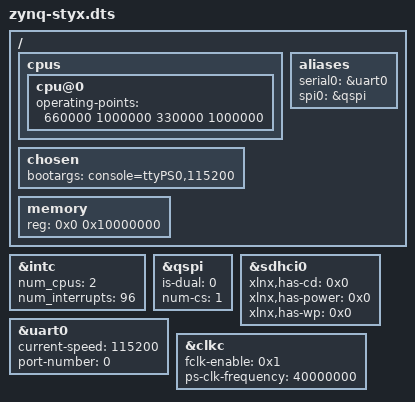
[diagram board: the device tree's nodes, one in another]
/*
 * CAUTION: This file is automatically generated by Xilinx.
 * Version:  
 * Today is: Thu Aug 11 10:48:36 2016
*/


/dts-v1/;
/include/ "zynq-7000.dtsi"
/ {
	cpus {
		cpu@0 {
			operating-points = <660000 1000000 330000 1000000>;
		};
	};
	chosen {
		bootargs = "console=ttyPS0,115200";
	};
	aliases {
		serial0 = &uart0;
		spi0 = &qspi;
	};
	memory {
		device_type = "memory";
		reg = <0x0 0x10000000>;
	};
};
&intc {
	num_cpus = <2>;
	num_interrupts = <96>;
};
&qspi {
	is-dual = <0>;
	num-cs = <1>;
	status = "okay";
};
&sdhci0 {
	status = "okay";
	xlnx,has-cd = <0x0>;
	xlnx,has-power = <0x0>;
	xlnx,has-wp = <0x0>;
};
&uart0 {
	current-speed = <115200>;
	device_type = "serial";
	port-number = <0>;
	status = "okay";
};
&clkc {
	fclk-enable = <0x1>;
	ps-clk-frequency = <40000000>;
};
